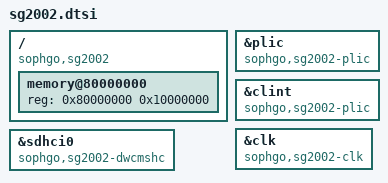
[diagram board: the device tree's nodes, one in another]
// SPDX-License-Identifier: (GPL-2.0 OR MIT)
/*
 * Copyright (C) 2024 Thomas Bonnefille <thomas.bonnefille@bootlin.com>
 */

/dts-v1/;

#include <dt-bindings/interrupt-controller/irq.h>
#include "cv18xx.dtsi"

/ {
	compatible = "sophgo,sg2002";

	memory@80000000 {
		device_type = "memory";
		reg = <0x80000000 0x10000000>;
	};
};

&plic {
	compatible = "sophgo,sg2002-plic", "sophgo,cv1800b-plic", "thead,c900-plic";
};

&clint {
	compatible = "sophgo,sg2002-plic", "sophgo,cv1800b-clint", "thead,c900-clint";
};

&clk {
	compatible = "sophgo,sg2002-clk", "sophgo,cv1800-clk";
};

&sdhci0 {
	compatible = "sophgo,sg2002-dwcmshc", "sophgo,cv1800b-dwcmshc";
};
